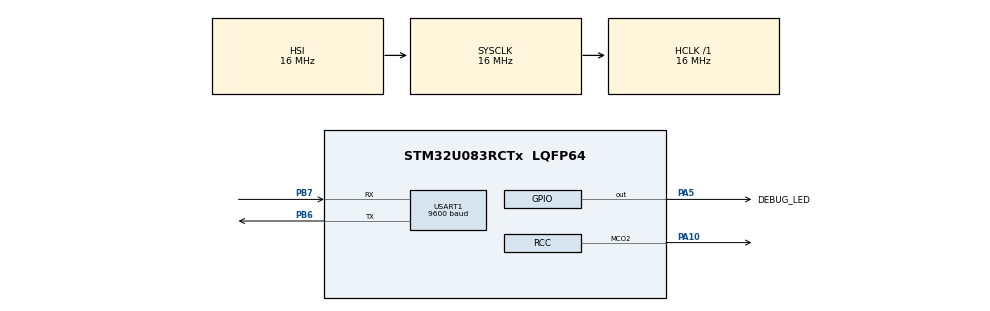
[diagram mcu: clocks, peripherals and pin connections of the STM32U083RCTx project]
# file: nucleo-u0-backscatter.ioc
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Mcu.Family=STM32U0
Mcu.Name=STM32U083RCTx
Mcu.Package=LQFP64
NVIC.PriorityGroup=NVIC_PRIORITYGROUP_2
PA5.GPIO_Label=DEBUG_LED
PA5.Signal=GPIO_Output
PA10.Mode=Clock-out-2
PA10.Signal=RCC_MCO2
PB6.Mode=Asynchronous
PB6.Signal=USART1_TX
PB7.Mode=Asynchronous
PB7.Signal=USART1_RX
ProjectManager.HeapSize=0x200
ProjectManager.StackSize=0x400
ProjectManager.TargetToolchain=Makefile
RCC.AHBFreq_Value=16000000
RCC.CortexFreq_Value=16000000
RCC.HCLKFreq_Value=16000000
RCC.HSE_VALUE=4000000
RCC.HSI48_VALUE=48000000
RCC.HSI_VALUE=16000000
RCC.LSE_VALUE=32768
RCC.MSI_VALUE=4000000
RCC.RCC_MCO2Div=RCC_MCO2DIV_8
RCC.RCC_MCO2Source=RCC_MCO2SOURCE_HSI48
RCC.SYSCLKFreq_VALUE=16000000
RCC.VCOOutputFreq_Value=64000000
USART1.BaudRate=9600
USART1.DataInvertParam=ADVFEATURE_DATAINV_ENABLE
USART1.Mode=MODE_TX
USART1.TxPinLevelInvertParam=ADVFEATURE_TXINV_ENABLE
USART1.VirtualMode-Asynchronous=VM_ASYNC
VP_PWR_VS_SECSignals.Mode=Security/Privilege
board=custom

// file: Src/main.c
/* USER CODE BEGIN Header */
/**
 ******************************************************************************
 * @file           : main.c
 * @brief          : Main program body
 ******************************************************************************
 * @attention
 *
 * Copyright (c) 2026 STMicroelectronics.
 * All rights reserved.
 *
 * This software is licensed under terms that can be found in the LICENSE file
 * in the root directory of this software component.
 * If no LICENSE file comes with this software, it is provided AS-IS.
 *
 ******************************************************************************
 */
/* USER CODE END Header */
#include "main.h"
#include "usart.h"
#include "gpio.h"

void SystemClock_Config(void);

int main(void)
{

  /* MCU Configuration--------------------------------------------------------*/

  /* Reset of all peripherals, Initializes the Flash interface and the Systick. */
  HAL_Init();

  /* Configure the system clock */
  SystemClock_Config();

  /* Initialize all configured peripherals */
  MX_GPIO_Init();
  MX_USART1_UART_Init();

  /* Infinite loop */
  /* USER CODE BEGIN WHILE */
    uint8_t msg[5] = "AMBER";
    while (1) {
    /* USER CODE END WHILE */

    /* USER CODE BEGIN 3 */

        // Ping the base station 4x for amplitude detection
        for (int i = 0; i < 4; i++) {
            // you will also see a '1' start bit
            // transmitted LSB first
            uint8_t ping[1] = {0b10101010};
            HAL_UART_Transmit(&huart1, ping, 1, 1000);
            HAL_Delay(100);
        }

        // Send the actual message
        HAL_GPIO_WritePin(DEBUG_LED_GPIO_Port, DEBUG_LED_Pin, GPIO_PIN_SET);
        HAL_UART_Transmit(&huart1, msg, 5, 1000);
        HAL_Delay(100);
        HAL_GPIO_WritePin(DEBUG_LED_GPIO_Port, DEBUG_LED_Pin, GPIO_PIN_RESET);
    }
  /* USER CODE END 3 */
}

void SystemClock_Config(void)
{
  RCC_OscInitTypeDef RCC_OscInitStruct = {0};
  RCC_ClkInitTypeDef RCC_ClkInitStruct = {0};

  /** Configure the main internal regulator output voltage
  */
  HAL_PWREx_ControlVoltageScaling(PWR_REGULATOR_VOLTAGE_SCALE2);

  /** Initializes the RCC Oscillators according to the specified parameters
  * in the RCC_OscInitTypeDef structure.
  */
  RCC_OscInitStruct.OscillatorType = RCC_OSCILLATORTYPE_HSI|RCC_OSCILLATORTYPE_HSI48;
  RCC_OscInitStruct.HSIState = RCC_HSI_ON;
  RCC_OscInitStruct.HSICalibrationValue = RCC_HSICALIBRATION_DEFAULT;
  RCC_OscInitStruct.HSI48State = RCC_HSI48_ON;
  RCC_OscInitStruct.PLL.PLLState = RCC_PLL_NONE;
  if (HAL_RCC_OscConfig(&RCC_OscInitStruct) != HAL_OK)
  {
    Error_Handler();
  }

  /** Initializes the CPU, AHB and APB buses clocks
  */
  RCC_ClkInitStruct.ClockType = RCC_CLOCKTYPE_HCLK|RCC_CLOCKTYPE_SYSCLK
                              |RCC_CLOCKTYPE_PCLK1;
  RCC_ClkInitStruct.SYSCLKSource = RCC_SYSCLKSOURCE_HSI;
  RCC_ClkInitStruct.AHBCLKDivider = RCC_SYSCLK_DIV1;
  RCC_ClkInitStruct.APB1CLKDivider = RCC_HCLK_DIV1;

  if (HAL_RCC_ClockConfig(&RCC_ClkInitStruct, FLASH_LATENCY_1) != HAL_OK)
  {
    Error_Handler();
  }
  HAL_RCC_MCOConfig(RCC_MCO2, RCC_MCO2SOURCE_HSI48, RCC_MCO2DIV_8);
}

void Error_Handler(void)
{
  /* USER CODE BEGIN Error_Handler_Debug */
    /* User can add his own implementation to report the HAL error return state
     */
    __disable_irq();
    while (1) {
    }
  /* USER CODE END Error_Handler_Debug */
}
#ifdef USE_FULL_ASSERT
/**
  * @brief  Reports the name of the source file and the source line number
  *         where the assert_param error has occurred.
  * @param  file: pointer to the source file name
  * @param  line: assert_param error line source number
  * @retval None
  */
void assert_failed(uint8_t *file, uint32_t line)
{
  /* USER CODE BEGIN 6 */
    /* User can add his own implementation to report the file name and line
       number, ex: printf("Wrong parameters value: file %s on line %d\r\n",
       file, line) */
  /* USER CODE END 6 */
}
#endif /* USE_FULL_ASSERT */
